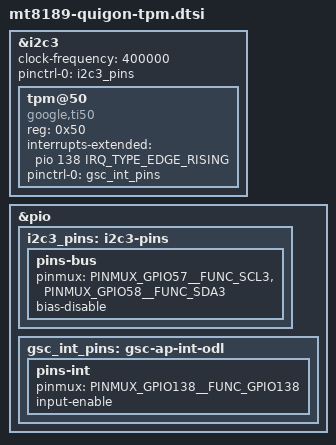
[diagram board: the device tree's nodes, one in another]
// SPDX-License-Identifier: (GPL-2.0 OR MIT)
/*
 * The GSC (Ti50) TPM on I2C3 0x50, interrupt on GPIO 138, as ChromeOS's skywalker DT has it. Gives /dev/tpm0 for
 * ChromeOS's gsctool (cros-run gsctool): CCD open, GSC version/console settings. Driver: tpm_tis_i2c_cr50.
 */
#include <dt-bindings/interrupt-controller/irq.h>

&i2c3 {
	clock-frequency = <400000>;
	pinctrl-names = "default";
	pinctrl-0 = <&i2c3_pins>;
	status = "okay";

	tpm@50 {
		compatible = "google,ti50", "google,cr50";
		reg = <0x50>;
		interrupts-extended = <&pio 138 IRQ_TYPE_EDGE_RISING>;
		pinctrl-names = "default";
		pinctrl-0 = <&gsc_int_pins>;
	};
};

&pio {
	i2c3_pins: i2c3-pins {
		pins-bus {
			pinmux = <PINMUX_GPIO57__FUNC_SCL3>,
				 <PINMUX_GPIO58__FUNC_SDA3>;
			bias-disable;
		};
	};

	gsc_int_pins: gsc-ap-int-odl {
		pins-int {
			pinmux = <PINMUX_GPIO138__FUNC_GPIO138>;
			input-enable;
		};
	};
};
